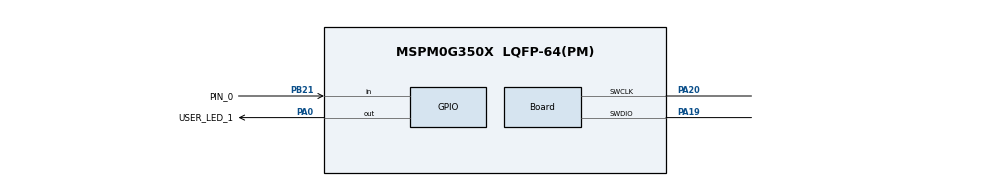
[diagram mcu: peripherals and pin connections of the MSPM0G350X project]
/**
 * @cliArgs --device "MSPM0G350X" --package "LQFP-64(PM)" --part "Default" --product "mspm0_sdk@2.00.01.00"
 * @versions {"tool":"1.20.0+3587"}
 */

/**
 * Import the modules used in this configuration.
 */
const GPIO          = scripting.addModule("/ti/driverlib/GPIO", {}, false);
const GPIO1         = GPIO.addInstance();
const GPIO2         = GPIO.addInstance();
const SYSCTL        = scripting.addModule("/ti/driverlib/SYSCTL");
const ProjectConfig = scripting.addModule("/ti/project_config/ProjectConfig");

/**
 * Write custom configuration values to the imported modules.
 */
GPIO1.$name                          = "GPIO_LEDS";
GPIO1.associatedPins[0].$name        = "USER_LED_1";
GPIO1.associatedPins[0].assignedPort = "PORTA";
GPIO1.associatedPins[0].assignedPin  = "0";
GPIO1.associatedPins[0].initialValue = "SET";
GPIO1.associatedPins[0].pin.$assign  = "PA0";

const Board                       = scripting.addModule("/ti/driverlib/Board", {}, false);
Board.peripheral.$assign          = "DEBUGSS";
Board.peripheral.swclkPin.$assign = "PA20";
Board.peripheral.swdioPin.$assign = "PA19";

GPIO2.$name                               = "GPIO_SWITCHES";
GPIO2.associatedPins[0].$name             = "PIN_0";
GPIO2.associatedPins[0].direction         = "INPUT";
GPIO2.associatedPins[0].interruptEn       = true;
GPIO2.associatedPins[0].polarity          = "RISE_FALL";
GPIO2.associatedPins[0].interruptPriority = "2";
GPIO2.associatedPins[0].internalResistor  = "PULL_UP";
GPIO2.associatedPins[0].pin.$assign       = "PB21";

SYSCTL.clockTreeEn = true;

ProjectConfig.deviceSpin = "MSPM0G3507";
